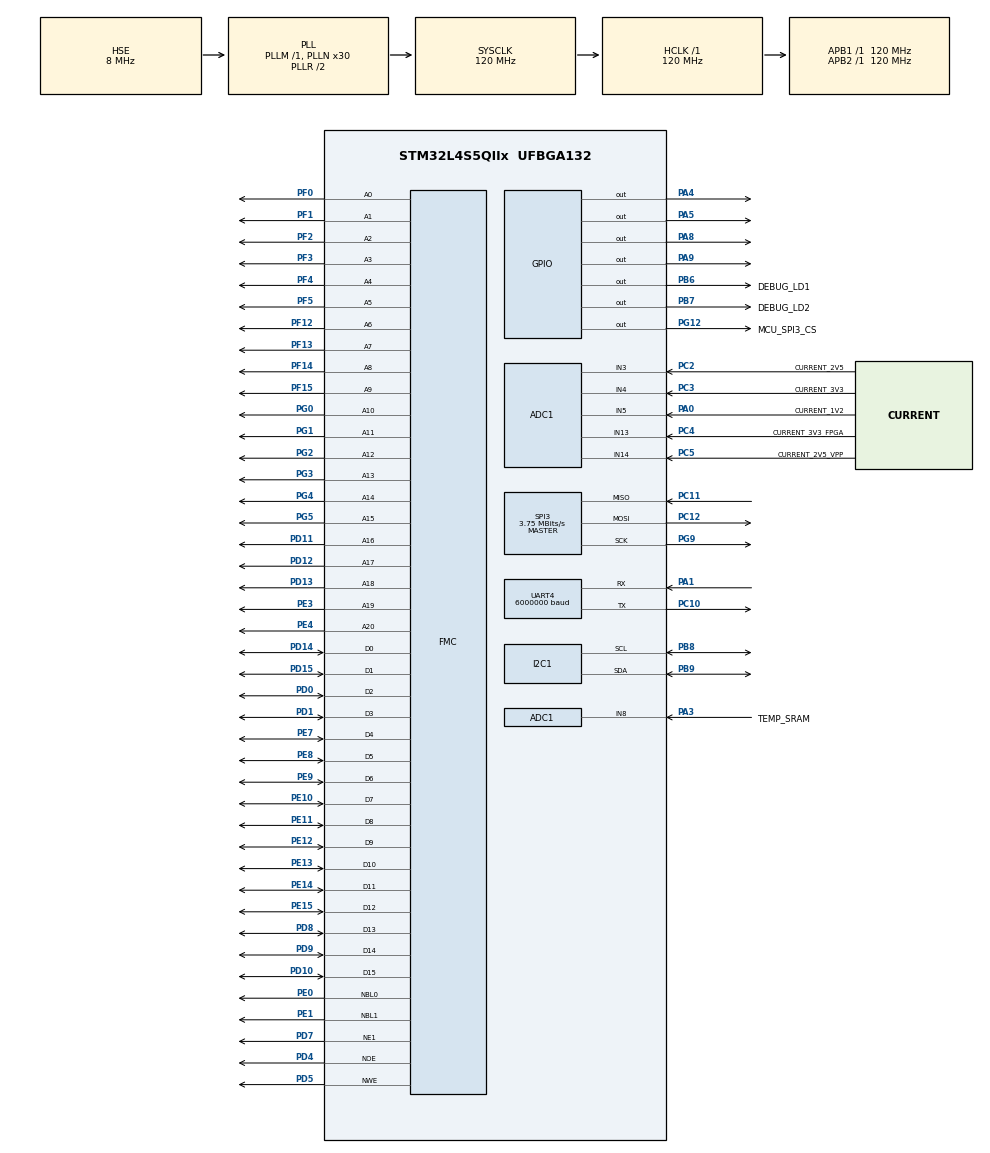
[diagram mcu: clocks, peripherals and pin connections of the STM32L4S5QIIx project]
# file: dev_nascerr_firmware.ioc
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ADC1.Channel-0\#ChannelRegularConversion=ADC_CHANNEL_3
ADC1.Channel-1\#ChannelRegularConversion=ADC_CHANNEL_4
ADC1.Channel-2\#ChannelRegularConversion=ADC_CHANNEL_5
ADC1.Channel-3\#ChannelRegularConversion=ADC_CHANNEL_13
ADC1.Channel-4\#ChannelRegularConversion=ADC_CHANNEL_14
ADC1.Channel-5\#ChannelRegularConversion=ADC_CHANNEL_8
ADC1.DMAContinuousRequests=ENABLE
ADC1.EOCSelection=ADC_EOC_SEQ_CONV
ADC1.ExternalTrigConv=ADC_EXTERNALTRIG_T2_TRGO
ADC1.NbrOfConversion=6
ADC1.NbrOfConversionFlag=1
ADC1.OffsetNumber-0\#ChannelRegularConversion=ADC_OFFSET_NONE
ADC1.OffsetNumber-1\#ChannelRegularConversion=ADC_OFFSET_NONE
ADC1.OffsetNumber-2\#ChannelRegularConversion=ADC_OFFSET_NONE
ADC1.OffsetNumber-3\#ChannelRegularConversion=ADC_OFFSET_NONE
ADC1.OffsetNumber-4\#ChannelRegularConversion=ADC_OFFSET_NONE
ADC1.OffsetNumber-5\#ChannelRegularConversion=ADC_OFFSET_NONE
ADC1.Rank-0\#ChannelRegularConversion=1
ADC1.Rank-1\#ChannelRegularConversion=2
ADC1.Rank-2\#ChannelRegularConversion=3
ADC1.Rank-3\#ChannelRegularConversion=4
ADC1.Rank-4\#ChannelRegularConversion=5
ADC1.Rank-5\#ChannelRegularConversion=6
ADC1.SamplingTime-0\#ChannelRegularConversion=ADC_SAMPLETIME_2CYCLES_5
ADC1.SamplingTime-1\#ChannelRegularConversion=ADC_SAMPLETIME_2CYCLES_5
ADC1.SamplingTime-2\#ChannelRegularConversion=ADC_SAMPLETIME_2CYCLES_5
ADC1.SamplingTime-3\#ChannelRegularConversion=ADC_SAMPLETIME_2CYCLES_5
ADC1.SamplingTime-4\#ChannelRegularConversion=ADC_SAMPLETIME_2CYCLES_5
ADC1.SamplingTime-5\#ChannelRegularConversion=ADC_SAMPLETIME_2CYCLES_5
ADC1.master=1
Dma.ADC1.2.Direction=DMA_PERIPH_TO_MEMORY
Dma.ADC1.2.EventEnable=DISABLE
Dma.ADC1.2.Instance=DMA1_Channel3
Dma.ADC1.2.MemDataAlignment=DMA_MDATAALIGN_WORD
Dma.ADC1.2.MemInc=DMA_MINC_ENABLE
Dma.ADC1.2.Mode=DMA_CIRCULAR
Dma.ADC1.2.PeriphDataAlignment=DMA_PDATAALIGN_WORD
Dma.ADC1.2.PeriphInc=DMA_PINC_DISABLE
Dma.ADC1.2.Polarity=HAL_DMAMUX_REQUEST_GEN_RISING
Dma.ADC1.2.Priority=DMA_PRIORITY_LOW
Dma.ADC1.2.RequestNumber=1
Dma.ADC1.2.SignalID=NONE
Dma.ADC1.2.SyncEnable=DISABLE
Dma.ADC1.2.SyncPolarity=HAL_DMAMUX_SYNC_NO_EVENT
Dma.ADC1.2.SyncRequestNumber=1
Dma.ADC1.2.SyncSignalID=NONE
Dma.Request0=SPI3_RX
Dma.Request1=SPI3_TX
Dma.Request2=ADC1
Dma.SPI3_RX.0.Direction=DMA_PERIPH_TO_MEMORY
Dma.SPI3_RX.0.EventEnable=DISABLE
Dma.SPI3_RX.0.Instance=DMA1_Channel1
Dma.SPI3_RX.0.MemDataAlignment=DMA_MDATAALIGN_BYTE
Dma.SPI3_RX.0.MemInc=DMA_MINC_ENABLE
Dma.SPI3_RX.0.Mode=DMA_NORMAL
Dma.SPI3_RX.0.PeriphDataAlignment=DMA_PDATAALIGN_BYTE
Dma.SPI3_RX.0.PeriphInc=DMA_PINC_DISABLE
Dma.SPI3_RX.0.Polarity=HAL_DMAMUX_REQUEST_GEN_RISING
Dma.SPI3_RX.0.Priority=DMA_PRIORITY_LOW
Dma.SPI3_RX.0.RequestNumber=1
Dma.SPI3_RX.0.SignalID=NONE
Dma.SPI3_RX.0.SyncEnable=DISABLE
Dma.SPI3_RX.0.SyncPolarity=HAL_DMAMUX_SYNC_NO_EVENT
Dma.SPI3_RX.0.SyncRequestNumber=1
Dma.SPI3_RX.0.SyncSignalID=NONE
Dma.SPI3_TX.1.Direction=DMA_MEMORY_TO_PERIPH
Dma.SPI3_TX.1.EventEnable=DISABLE
Dma.SPI3_TX.1.Instance=DMA1_Channel2
Dma.SPI3_TX.1.MemDataAlignment=DMA_MDATAALIGN_BYTE
Dma.SPI3_TX.1.MemInc=DMA_MINC_ENABLE
Dma.SPI3_TX.1.Mode=DMA_NORMAL
Dma.SPI3_TX.1.PeriphDataAlignment=DMA_PDATAALIGN_BYTE
Dma.SPI3_TX.1.PeriphInc=DMA_PINC_DISABLE
Dma.SPI3_TX.1.Polarity=HAL_DMAMUX_REQUEST_GEN_RISING
Dma.SPI3_TX.1.Priority=DMA_PRIORITY_LOW
Dma.SPI3_TX.1.RequestNumber=1
Dma.SPI3_TX.1.SignalID=NONE
Dma.SPI3_TX.1.SyncEnable=DISABLE
Dma.SPI3_TX.1.SyncPolarity=HAL_DMAMUX_SYNC_NO_EVENT
Dma.SPI3_TX.1.SyncRequestNumber=1
Dma.SPI3_TX.1.SyncSignalID=NONE
FMC.WriteFifo1=FMC_WRITE_FIFO_DISABLE
FMC.WriteOperation1=FMC_WRITE_OPERATION_ENABLE
FREERTOS.Tasks01=defaultTask,24,128,StartDefaultTask,Default,NULL,Dynamic,NULL,NULL
I2C1.OwnAddress=0x55
I2C1.Timing=0x30A175AB
IWDG.Prescaler=IWDG_PRESCALER_64
IWDG.Reload=500
Mcu.Family=STM32L4
Mcu.Name=STM32L4S5QIIx
Mcu.Package=UFBGA132
NVIC.DMA1_Channel1_IRQn=true\:5\:0\:false\:false\:true\:true\:false\:true\:true
NVIC.DMA1_Channel2_IRQn=true\:5\:0\:false\:false\:true\:true\:false\:true\:true
NVIC.DMA1_Channel3_IRQn=true\:5\:0\:false\:false\:true\:true\:false\:true\:true
NVIC.I2C1_EV_IRQn=true\:5\:0\:false\:false\:true\:true\:true\:true\:true
NVIC.PriorityGroup=NVIC_PRIORITYGROUP_4
NVIC.SPI3_IRQn=true\:5\:0\:false\:false\:true\:true\:true\:true\:true
PA0.GPIO_Label=CURRENT_1V2
PA0.Signal=ADCx_IN5
PA1.Mode=Asynchronous
PA1.Signal=UART4_RX
PA3.GPIO_Label=TEMP_SRAM
PA3.Signal=ADCx_IN8
PA4.GPIO_PuPd=GPIO_PULLDOWN
PA4.Signal=GPIO_Output
PA5.GPIO_PuPd=GPIO_PULLDOWN
PA5.Signal=GPIO_Output
PA8.GPIO_PuPd=GPIO_PULLDOWN
PA8.Signal=GPIO_Output
PA9.GPIO_PuPd=GPIO_PULLDOWN
PA9.Signal=GPIO_Output
PB6.GPIO_Label=DEBUG_LD1
PB6.Signal=GPIO_Output
PB7.GPIO_Label=DEBUG_LD2
PB7.Signal=GPIO_Output
PB8.Mode=I2C
PB8.Signal=I2C1_SCL
PB9.Mode=I2C
PB9.Signal=I2C1_SDA
PC10.Mode=Asynchronous
PC10.Signal=UART4_TX
PC11.Mode=Full_Duplex_Master
PC11.Signal=SPI3_MISO
PC12.Mode=Full_Duplex_Master
PC12.Signal=SPI3_MOSI
PC2.GPIO_Label=CURRENT_2V5
PC2.Signal=ADCx_IN3
PC3.GPIO_Label=CURRENT_3V3
PC3.Signal=ADCx_IN4
PC4.GPIO_Label=CURRENT_3V3_FPGA
PC4.Signal=ADCx_IN13
PC5.GPIO_Label=CURRENT_2V5_VPP
PC5.Signal=ADCx_IN14
PD0.Signal=FMC_D2_DA2
PD1.Signal=FMC_D3_DA3
PD10.Signal=FMC_D15_DA15
PD11.Signal=FMC_A16_CLE
PD12.Signal=FMC_A17_ALE
PD13.Signal=FMC_A18
PD14.Signal=FMC_D0_DA0
PD15.Signal=FMC_D1_DA1
PD4.Signal=FMC_NOE
PD5.Signal=FMC_NWE
PD7.Mode=NorPsramChipSelect1_1
PD7.Signal=FMC_NE1
PD8.Signal=FMC_D13_DA13
PD9.Signal=FMC_D14_DA14
PE0.Signal=FMC_NBL0
PE1.Signal=FMC_NBL1
PE10.Signal=FMC_D7_DA7
PE11.Signal=FMC_D8_DA8
PE12.Signal=FMC_D9_DA9
PE13.Signal=FMC_D10_DA10
PE14.Signal=FMC_D11_DA11
PE15.Signal=FMC_D12_DA12
PE3.Signal=FMC_A19
PE4.Signal=FMC_A20
PE7.Signal=FMC_D4_DA4
PE8.Signal=FMC_D5_DA5
PE9.Signal=FMC_D6_DA6
PF0.Signal=FMC_A0
PF1.Signal=FMC_A1
PF12.Signal=FMC_A6
PF13.Signal=FMC_A7
PF14.Signal=FMC_A8
PF15.Signal=FMC_A9
PF2.Signal=FMC_A2
PF3.Signal=FMC_A3
PF4.Signal=FMC_A4
PF5.Signal=FMC_A5
PG0.Signal=FMC_A10
PG1.Signal=FMC_A11
PG12.GPIO_Label=MCU_SPI3_CS
PG12.GPIO_Speed=GPIO_SPEED_FREQ_HIGH
PG12.PinState=GPIO_PIN_SET
PG12.Signal=GPIO_Output
PG2.Signal=FMC_A12
PG3.Signal=FMC_A13
PG4.Signal=FMC_A14
PG5.Signal=FMC_A15
PG9.Mode=Full_Duplex_Master
PG9.Signal=SPI3_SCK
PH0-OSC_IN\ (PH0).Mode=HSE-External-Oscillator
PH0-OSC_IN\ (PH0).Signal=RCC_OSC_IN
PH1-OSC_OUT\ (PH1).Mode=HSE-External-Oscillator
PH1-OSC_OUT\ (PH1).Signal=RCC_OSC_OUT
ProjectManager.HeapSize=0x200
ProjectManager.StackSize=0x400
ProjectManager.TargetToolchain=STM32CubeIDE
RCC.ADCFreq_Value=32000000
RCC.AHBFreq_Value=120000000
RCC.APB1Freq_Value=120000000
RCC.APB1TimFreq_Value=120000000
RCC.APB2Freq_Value=120000000
RCC.APB2TimFreq_Value=120000000
RCC.CortexFreq_Value=120000000
RCC.HCLKFreq_Value=120000000
RCC.HSE_VALUE=8000000
RCC.HSI48_VALUE=48000000
RCC.HSI_VALUE=16000000
RCC.LSE_VALUE=32768
RCC.MSI_VALUE=4000000
RCC.PLLN=30
RCC.PLLSourceVirtual=RCC_PLLSOURCE_HSE
RCC.SYSCLKFreq_VALUE=120000000
RCC.SYSCLKSource=RCC_SYSCLKSOURCE_PLLCLK
RCC.USBFreq_Value=32000000
RCC.VCOOutputFreq_Value=240000000
SH.ADCx_IN13.0=ADC1_IN13,IN13-Single-Ended
SH.ADCx_IN14.0=ADC1_IN14,IN14-Single-Ended
SH.ADCx_IN3.0=ADC1_IN3,IN3-Single-Ended
SH.ADCx_IN4.0=ADC1_IN4,IN4-Single-Ended
SH.ADCx_IN5.0=ADC1_IN5,IN5-Single-Ended
SH.ADCx_IN8.0=ADC1_IN8,IN8-Single-Ended
SH.FMC_A0.0=FMC_A0,21b-a1
SH.FMC_A1.0=FMC_A1,21b-a1
SH.FMC_A10.0=FMC_A10,21b-a1
SH.FMC_A11.0=FMC_A11,21b-a1
SH.FMC_A12.0=FMC_A12,21b-a1
SH.FMC_A13.0=FMC_A13,21b-a1
SH.FMC_A14.0=FMC_A14,21b-a1
SH.FMC_A15.0=FMC_A15,21b-a1
SH.FMC_A16_CLE.0=FMC_A16,21b-a1
SH.FMC_A17_ALE.0=FMC_A17,21b-a1
SH.FMC_A18.0=FMC_A18,21b-a1
SH.FMC_A19.0=FMC_A19,21b-a1
SH.FMC_A2.0=FMC_A2,21b-a1
SH.FMC_A20.0=FMC_A20,21b-a1
SH.FMC_A3.0=FMC_A3,21b-a1
SH.FMC_A4.0=FMC_A4,21b-a1
SH.FMC_A5.0=FMC_A5,21b-a1
SH.FMC_A6.0=FMC_A6,21b-a1
SH.FMC_A7.0=FMC_A7,21b-a1
SH.FMC_A8.0=FMC_A8,21b-a1
SH.FMC_A9.0=FMC_A9,21b-a1
SH.FMC_D0_DA0.0=FMC_D0,16b-d1
SH.FMC_D10_DA10.0=FMC_D10,16b-d1
SH.FMC_D11_DA11.0=FMC_D11,16b-d1
SH.FMC_D12_DA12.0=FMC_D12,16b-d1
SH.FMC_D13_DA13.0=FMC_D13,16b-d1
SH.FMC_D14_DA14.0=FMC_D14,16b-d1
SH.FMC_D15_DA15.0=FMC_D15,16b-d1
SH.FMC_D1_DA1.0=FMC_D1,16b-d1
SH.FMC_D2_DA2.0=FMC_D2,16b-d1
SH.FMC_D3_DA3.0=FMC_D3,16b-d1
SH.FMC_D4_DA4.0=FMC_D4,16b-d1
SH.FMC_D5_DA5.0=FMC_D5,16b-d1
SH.FMC_D6_DA6.0=FMC_D6,16b-d1
SH.FMC_D7_DA7.0=FMC_D7,16b-d1
SH.FMC_D8_DA8.0=FMC_D8,16b-d1
SH.FMC_D9_DA9.0=FMC_D9,16b-d1
SH.FMC_NBL0.0=FMC_NBL0,2ByteEnable1
SH.FMC_NBL1.0=FMC_NBL1,2ByteEnable1
SH.FMC_NOE.0=FMC_NOE,Sram1
SH.FMC_NWE.0=FMC_NWE,Sram1
SPI3.BaudRatePrescaler=SPI_BAUDRATEPRESCALER_32
SPI3.CalculateBaudRate=3.75 MBits/s
SPI3.DataSize=SPI_DATASIZE_8BIT
SPI3.Direction=SPI_DIRECTION_2LINES
SPI3.Mode=SPI_MODE_MASTER
SPI3.VirtualType=VM_MASTER
TIM2.Period=12000
TIM2.TIM_MasterOutputTrigger=TIM_TRGO_UPDATE
UART4.BaudRate=6000000
VP_FREERTOS_VS_CMSIS_V2.Mode=CMSIS_V2
VP_IWDG_VS_IWDG.Mode=IWDG_Activate
VP_TIM2_VS_ClockSourceINT.Mode=Internal
board=custom

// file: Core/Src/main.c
/* USER CODE BEGIN Header */
/**
  ******************************************************************************
  * @file           : main.c
  * @brief          : Main program body
  ******************************************************************************
  * @attention
  *
  * Copyright (c) 2024 STMicroelectronics.
  * All rights reserved.
  *
  * This software is licensed under terms that can be found in the LICENSE file
  * in the root directory of this software component.
  * If no LICENSE file comes with this software, it is provided AS-IS.
  *
  ******************************************************************************
  */
/* USER CODE END Header */
#include "main.h"
#include "cmsis_os.h"
#include "adc.h"
#include "dma.h"
#include "i2c.h"
#include "iwdg.h"
#include "spi.h"
#include "tim.h"
#include "usart.h"
#include "gpio.h"
#include "fmc.h"

/* USER CODE BEGIN Includes */
#include <stdio.h>

#include "i2c_slave.h"
#include "NASCERR_Flash.h"
/* USER CODE END Includes */

/* USER CODE BEGIN PD */

/* Enum to define log levels */

/* USER CODE END PD */

/* USER CODE BEGIN PV */
uint32_t adc_buf[BUFFER_SIZE], adc_val = 0;
/* USER CODE END PV */

void SystemClock_Config(void);
void MX_FREERTOS_Init(void);

int main(void)
{

  /* MCU Configuration--------------------------------------------------------*/

  /* Reset of all peripherals, Initializes the Flash interface and the Systick. */
  HAL_Init();

  /* Configure the system clock */
  SystemClock_Config();

  /* Initialize all configured peripherals */
  MX_GPIO_Init();
  MX_DMA_Init();
  MX_UART4_Init();
  MX_I2C1_Init();
  MX_FMC_Init();
  MX_SPI3_Init();
  MX_ADC1_Init();
  MX_TIM2_Init();
  /* USER CODE BEGIN 2 */
#if !SOFTWARE_DEBUG
  MX_IWDG_Init();
#endif
  i2c_slave_init();
  DEBUG_PRINT(LOG_DEBUG, "NASCERR Inicializado... \r\n");

  nascerr_flash_init();
//  HAL_GPIO_WritePin(GPIOB, DEBUG_LD2_Pin, GPIO_PIN_SET);
  NASCERR_HWRead_Start(hadc1, htim2, adc_buf);
  /* USER CODE END 2 */

  /* Init scheduler */
  osKernelInitialize();

  /* Call init function for freertos objects (in cmsis_os2.c) */
  MX_FREERTOS_Init();

  /* Start scheduler */
  osKernelStart();

  /* We should never get here as control is now taken by the scheduler */

  /* Infinite loop */
  while (1)
  {

  }
}

void SystemClock_Config(void)
{
  RCC_OscInitTypeDef RCC_OscInitStruct = {0};
  RCC_ClkInitTypeDef RCC_ClkInitStruct = {0};

  /** Configure the main internal regulator output voltage
  */
  if (HAL_PWREx_ControlVoltageScaling(PWR_REGULATOR_VOLTAGE_SCALE1_BOOST) != HAL_OK)
  {
    Error_Handler();
  }

  /** Initializes the RCC Oscillators according to the specified parameters
  * in the RCC_OscInitTypeDef structure.
  */
  RCC_OscInitStruct.OscillatorType = RCC_OSCILLATORTYPE_LSI|RCC_OSCILLATORTYPE_HSE;
  RCC_OscInitStruct.HSEState = RCC_HSE_ON;
  RCC_OscInitStruct.LSIState = RCC_LSI_ON;
  RCC_OscInitStruct.PLL.PLLState = RCC_PLL_ON;
  RCC_OscInitStruct.PLL.PLLSource = RCC_PLLSOURCE_HSE;
  RCC_OscInitStruct.PLL.PLLM = 1;
  RCC_OscInitStruct.PLL.PLLN = 30;
  RCC_OscInitStruct.PLL.PLLP = RCC_PLLP_DIV2;
  RCC_OscInitStruct.PLL.PLLQ = RCC_PLLQ_DIV2;
  RCC_OscInitStruct.PLL.PLLR = RCC_PLLR_DIV2;
  if (HAL_RCC_OscConfig(&RCC_OscInitStruct) != HAL_OK)
  {
    Error_Handler();
  }

  /** Initializes the CPU, AHB and APB buses clocks
  */
  RCC_ClkInitStruct.ClockType = RCC_CLOCKTYPE_HCLK|RCC_CLOCKTYPE_SYSCLK
                              |RCC_CLOCKTYPE_PCLK1|RCC_CLOCKTYPE_PCLK2;
  RCC_ClkInitStruct.SYSCLKSource = RCC_SYSCLKSOURCE_PLLCLK;
  RCC_ClkInitStruct.AHBCLKDivider = RCC_SYSCLK_DIV1;
  RCC_ClkInitStruct.APB1CLKDivider = RCC_HCLK_DIV1;
  RCC_ClkInitStruct.APB2CLKDivider = RCC_HCLK_DIV1;

  if (HAL_RCC_ClockConfig(&RCC_ClkInitStruct, FLASH_LATENCY_5) != HAL_OK)
  {
    Error_Handler();
  }
}

/* USER CODE BEGIN 4 */
//void HAL_ADC_ConvCpltCallback(ADC_HandleTypeDef *hadc){
//	HAL_GPIO_WritePin(GPIOB, DEBUG_LD2_Pin, GPIO_PIN_SET);
//}
/* USER CODE END 4 */

void Error_Handler(void)
{
  __disable_irq();
  while (1)
  {
  }
}

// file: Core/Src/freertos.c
/* USER CODE BEGIN Header */
/**
  ******************************************************************************
  * File Name          : freertos.c
  * Description        : Code for freertos applications
  ******************************************************************************
  * @attention
  *
  * Copyright (c) 2024 STMicroelectronics.
  * All rights reserved.
  *
  * This software is licensed under terms that can be found in the LICENSE file
  * in the root directory of this software component.
  * If no LICENSE file comes with this software, it is provided AS-IS.
  *
  ******************************************************************************
  */
/* USER CODE END Header */

#include "FreeRTOS.h"
#include "task.h"
#include "main.h"
#include "cmsis_os.h"

/* USER CODE BEGIN Includes */
#include "NASCERR_Tasks.h"
/* USER CODE END Includes */

/* Definitions for defaultTask */
osThreadId_t defaultTaskHandle;
const osThreadAttr_t defaultTask_attributes = {
  .name = "defaultTask",
  .stack_size = 128 * 4,
  .priority = (osPriority_t) osPriorityNormal,
};

void StartDefaultTask(void *argument);

void MX_FREERTOS_Init(void); /* (MISRA C 2004 rule 8.1) */

void MX_FREERTOS_Init(void) {

  /* Create the thread(s) */
  /* creation of defaultTask */
  defaultTaskHandle = osThreadNew(StartDefaultTask, NULL, &defaultTask_attributes);

  /* USER CODE BEGIN RTOS_THREADS */
	defaultTaskHandle = osThreadNew(receive_dataResp, NULL, NULL);
  /* add threads, ... */
  /* USER CODE END RTOS_THREADS */

}

void StartDefaultTask(void *argument)
{
  for(;;)
  {
    osDelay(1);
  }
}
